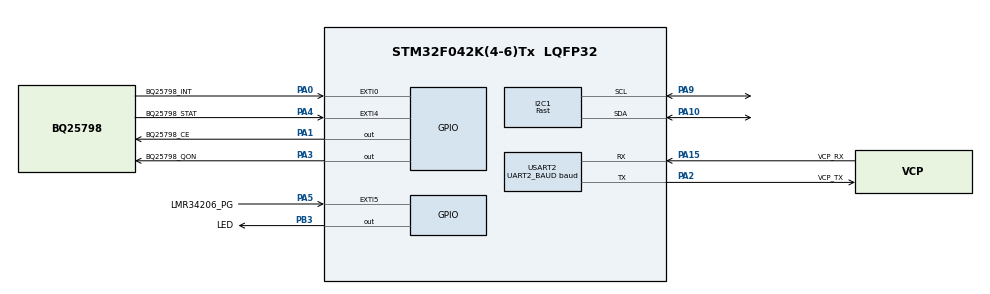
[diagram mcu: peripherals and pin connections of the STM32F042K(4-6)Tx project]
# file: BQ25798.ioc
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Dma.I2C1_RX.0.Direction=DMA_PERIPH_TO_MEMORY
Dma.I2C1_RX.0.Instance=DMA1_Channel3
Dma.I2C1_RX.0.MemDataAlignment=DMA_MDATAALIGN_BYTE
Dma.I2C1_RX.0.MemInc=DMA_MINC_ENABLE
Dma.I2C1_RX.0.Mode=DMA_NORMAL
Dma.I2C1_RX.0.PeriphDataAlignment=DMA_PDATAALIGN_BYTE
Dma.I2C1_RX.0.PeriphInc=DMA_PINC_DISABLE
Dma.I2C1_RX.0.Priority=DMA_PRIORITY_LOW
Dma.I2C1_TX.1.Direction=DMA_MEMORY_TO_PERIPH
Dma.I2C1_TX.1.Instance=DMA1_Channel2
Dma.I2C1_TX.1.MemDataAlignment=DMA_MDATAALIGN_BYTE
Dma.I2C1_TX.1.MemInc=DMA_MINC_ENABLE
Dma.I2C1_TX.1.Mode=DMA_NORMAL
Dma.I2C1_TX.1.PeriphDataAlignment=DMA_PDATAALIGN_BYTE
Dma.I2C1_TX.1.PeriphInc=DMA_PINC_DISABLE
Dma.I2C1_TX.1.Priority=DMA_PRIORITY_LOW
Dma.Request0=I2C1_RX
Dma.Request1=I2C1_TX
I2C1.I2C_Speed_Mode=I2C_Fast
I2C1.Timing=0x0000020B
Mcu.Family=STM32F0
Mcu.Name=STM32F042K(4-6)Tx
Mcu.Package=LQFP32
Mcu.UserConstants=TIMER1_PERIOD,1249;UART2_BAUD,115200;TIMER_PRESCALER,799;UART_DUMP,1
NVIC.DMA1_Channel2_3_IRQn=true\:0\:0\:false\:false\:true\:false\:true\:true
NVIC.EXTI0_1_IRQn=true\:1\:0\:true\:false\:true\:true\:true\:true
NVIC.EXTI4_15_IRQn=true\:1\:0\:true\:false\:true\:true\:true\:true
NVIC.I2C1_IRQn=true\:0\:0\:true\:false\:true\:true\:true\:true
NVIC.TIM1_BRK_UP_TRG_COM_IRQn=true\:2\:0\:true\:false\:true\:true\:true\:true
NVIC.USART2_IRQn=true\:3\:0\:true\:false\:true\:true\:true\:true
PA0.GPIO_Label=BQ25798_INT
PA0.GPIO_ModeDefaultEXTI=GPIO_MODE_IT_FALLING
PA0.Signal=GPXTI0
PA1.GPIO_Label=BQ25798_CE
PA1.PinState=GPIO_PIN_SET
PA1.Signal=GPIO_Output
PA10.GPIO_Pu=GPIO_PULLUP
PA10.Mode=I2C
PA10.Signal=I2C1_SDA
PA13.GPIO_Label=SWDIO
PA13.Mode=Serial_Wire
PA13.Signal=SYS_SWDIO
PA14.GPIO_Label=SWCLK
PA14.Mode=Serial_Wire
PA14.Signal=SYS_SWCLK
PA15.GPIO_Label=VCP_RX
PA15.Mode=Asynchronous
PA15.Signal=USART2_RX
PA2.GPIO_Label=VCP_TX
PA2.Mode=Asynchronous
PA2.Signal=USART2_TX
PA3.GPIO_Label=BQ25798_QON
PA3.PinState=GPIO_PIN_SET
PA3.Signal=GPIO_Output
PA4.GPIO_Label=BQ25798_STAT
PA4.Signal=GPXTI4
PA5.GPIO_Label=LMR34206_PG
PA5.GPIO_ModeDefaultEXTI=GPIO_MODE_IT_RISING_FALLING
PA5.Signal=GPXTI5
PA9.GPIO_Pu=GPIO_PULLUP
PA9.Mode=I2C
PA9.Signal=I2C1_SCL
PB3.GPIO_Label=LED
PB3.Signal=GPIO_Output
PF0-OSC_IN.GPIO_Label=MCO
PF0-OSC_IN.Mode=HSE-External-Clock-Source
PF0-OSC_IN.Signal=RCC_OSC_IN
ProjectManager.HeapSize=0x200
ProjectManager.StackSize=0x400
ProjectManager.TargetToolchain=STM32CubeIDE
TIM1.Period=TIMER1_PERIOD
TIM1.Prescaler=TIMER_PRESCALER
USART2.BaudRate=UART2_BAUD
USART2.VirtualMode-Asynchronous=VM_ASYNC
VP_TIM1_VS_ClockSourceINT.Mode=Internal
board=NUCLEO-F042K6

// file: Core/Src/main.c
/* USER CODE BEGIN Header */
/**
 ******************************************************************************
 * @file           : main.c
 * @brief          : Main program body
 ******************************************************************************
 * @attention
 *
 * Copyright (c) 2023 STMicroelectronics.
 * All rights reserved.
 *
 * This software is licensed under terms that can be found in the LICENSE file
 * in the root directory of this software component.
 * If no LICENSE file comes with this software, it is provided AS-IS.
 *
 ******************************************************************************
 */
/* USER CODE END Header */
#include "main.h"

/* USER CODE BEGIN Includes */
#include <stdio.h>
#include "bq25798.h"
/* USER CODE END Includes */

I2C_HandleTypeDef hi2c1;
DMA_HandleTypeDef hdma_i2c1_rx;
DMA_HandleTypeDef hdma_i2c1_tx;

TIM_HandleTypeDef htim1;

UART_HandleTypeDef huart2;

/* USER CODE BEGIN PV */
bq25798_t const *BQ25798;
/* USER CODE END PV */

void SystemClock_Config(void);
static void MX_GPIO_Init(void);
static void MX_DMA_Init(void);
static void MX_USART2_UART_Init(void);
static void MX_TIM1_Init(void);
static void MX_I2C1_Init(void);

int main(void)
{

	/* MCU Configuration--------------------------------------------------------*/

	/* Reset of all peripherals, Initializes the Flash interface and the Systick. */
	HAL_Init();

	/* Configure the system clock */
	SystemClock_Config();

	/* Initialize all configured peripherals */
	MX_GPIO_Init();
	MX_DMA_Init();
	MX_USART2_UART_Init();
	MX_TIM1_Init();
	MX_I2C1_Init();
	/* USER CODE BEGIN 2 */

	// order is important!
	BQ25798 = bq25798_ctor(&hi2c1);  // initialize device
	HAL_NVIC_EnableIRQ(TIM1_BRK_UP_TRG_COM_IRQn);  // enable timer1 interrupts

//	printf("\r\n---\r\n");	// start marker
	/* USER CODE END 2 */

	/* Infinite loop */
	while(1)
		{

		}
}

void SystemClock_Config(void)
{
	RCC_OscInitTypeDef RCC_OscInitStruct =
		{0};
	RCC_ClkInitTypeDef RCC_ClkInitStruct =
		{0};
	RCC_PeriphCLKInitTypeDef PeriphClkInit =
		{0};

	/** Initializes the RCC Oscillators according to the specified parameters
	 * in the RCC_OscInitTypeDef structure.
	 */
	RCC_OscInitStruct.OscillatorType = RCC_OSCILLATORTYPE_HSI;
	RCC_OscInitStruct.HSIState = RCC_HSI_ON;
	RCC_OscInitStruct.HSICalibrationValue = RCC_HSICALIBRATION_DEFAULT;
	RCC_OscInitStruct.PLL.PLLState = RCC_PLL_NONE;
	if(HAL_RCC_OscConfig(&RCC_OscInitStruct) != HAL_OK)
		{
			Error_Handler();
		}

	/** Initializes the CPU, AHB and APB buses clocks
	 */
	RCC_ClkInitStruct.ClockType = RCC_CLOCKTYPE_HCLK | RCC_CLOCKTYPE_SYSCLK | RCC_CLOCKTYPE_PCLK1;
	RCC_ClkInitStruct.SYSCLKSource = RCC_SYSCLKSOURCE_HSI;
	RCC_ClkInitStruct.AHBCLKDivider = RCC_SYSCLK_DIV1;
	RCC_ClkInitStruct.APB1CLKDivider = RCC_HCLK_DIV1;

	if(HAL_RCC_ClockConfig(&RCC_ClkInitStruct, FLASH_LATENCY_0) != HAL_OK)
		{
			Error_Handler();
		}
	PeriphClkInit.PeriphClockSelection = RCC_PERIPHCLK_I2C1;
	PeriphClkInit.I2c1ClockSelection = RCC_I2C1CLKSOURCE_HSI;
	if(HAL_RCCEx_PeriphCLKConfig(&PeriphClkInit) != HAL_OK)
		{
			Error_Handler();
		}
}

static void MX_I2C1_Init(void)
{

	hi2c1.Instance = I2C1;
	hi2c1.Init.Timing = 0x0000020B;
	hi2c1.Init.OwnAddress1 = 0;
	hi2c1.Init.AddressingMode = I2C_ADDRESSINGMODE_7BIT;
	hi2c1.Init.DualAddressMode = I2C_DUALADDRESS_DISABLE;
	hi2c1.Init.OwnAddress2 = 0;
	hi2c1.Init.OwnAddress2Masks = I2C_OA2_NOMASK;
	hi2c1.Init.GeneralCallMode = I2C_GENERALCALL_DISABLE;
	hi2c1.Init.NoStretchMode = I2C_NOSTRETCH_DISABLE;
	if(HAL_I2C_Init(&hi2c1) != HAL_OK)
		{
			Error_Handler();
		}

	/** Configure Analogue filter
	 */
	if(HAL_I2CEx_ConfigAnalogFilter(&hi2c1, I2C_ANALOGFILTER_ENABLE) != HAL_OK)
		{
			Error_Handler();
		}

	/** Configure Digital filter
	 */
	if(HAL_I2CEx_ConfigDigitalFilter(&hi2c1, 0) != HAL_OK)
		{
			Error_Handler();
		}

}

static void MX_TIM1_Init(void)
{

	TIM_ClockConfigTypeDef sClockSourceConfig =
		{0};
	TIM_MasterConfigTypeDef sMasterConfig =
		{0};

	htim1.Instance = TIM1;
	htim1.Init.Prescaler = TIMER_PRESCALER;
	htim1.Init.CounterMode = TIM_COUNTERMODE_UP;
	htim1.Init.Period = TIMER1_PERIOD;
	htim1.Init.ClockDivision = TIM_CLOCKDIVISION_DIV1;
	htim1.Init.RepetitionCounter = 0;
	htim1.Init.AutoReloadPreload = TIM_AUTORELOAD_PRELOAD_DISABLE;
	if(HAL_TIM_Base_Init(&htim1) != HAL_OK)
		{
			Error_Handler();
		}
	sClockSourceConfig.ClockSource = TIM_CLOCKSOURCE_INTERNAL;
	if(HAL_TIM_ConfigClockSource(&htim1, &sClockSourceConfig) != HAL_OK)
		{
			Error_Handler();
		}
	sMasterConfig.MasterOutputTrigger = TIM_TRGO_RESET;
	sMasterConfig.MasterSlaveMode = TIM_MASTERSLAVEMODE_DISABLE;
	if(HAL_TIMEx_MasterConfigSynchronization(&htim1, &sMasterConfig) != HAL_OK)
		{
			Error_Handler();
		}
	/* USER CODE BEGIN TIM1_Init 2 */
	HAL_TIM_Base_Start_IT(&htim1);	// start the timer
	/* USER CODE END TIM1_Init 2 */

}

static void MX_USART2_UART_Init(void)
{

	huart2.Instance = USART2;
	huart2.Init.BaudRate = UART2_BAUD;
	huart2.Init.WordLength = UART_WORDLENGTH_8B;
	huart2.Init.StopBits = UART_STOPBITS_1;
	huart2.Init.Parity = UART_PARITY_NONE;
	huart2.Init.Mode = UART_MODE_TX_RX;
	huart2.Init.HwFlowCtl = UART_HWCONTROL_NONE;
	huart2.Init.OverSampling = UART_OVERSAMPLING_16;
	huart2.Init.OneBitSampling = UART_ONE_BIT_SAMPLE_DISABLE;
	huart2.AdvancedInit.AdvFeatureInit = UART_ADVFEATURE_NO_INIT;
	if(HAL_UART_Init(&huart2) != HAL_OK)
		{
			Error_Handler();
		}

}

static void MX_DMA_Init(void)
{

	/* DMA controller clock enable */
	__HAL_RCC_DMA1_CLK_ENABLE();

	/* DMA interrupt init */
	/* DMA1_Channel2_3_IRQn interrupt configuration */
	HAL_NVIC_SetPriority(DMA1_Channel2_3_IRQn, 0, 0);
	HAL_NVIC_EnableIRQ(DMA1_Channel2_3_IRQn);

}

static void MX_GPIO_Init(void)
{
	GPIO_InitTypeDef GPIO_InitStruct =
		{0};

	/* GPIO Ports Clock Enable */
	__HAL_RCC_GPIOF_CLK_ENABLE();
	__HAL_RCC_GPIOA_CLK_ENABLE();
	__HAL_RCC_GPIOB_CLK_ENABLE();

	/*Configure GPIO pin Output Level */
	HAL_GPIO_WritePin(GPIOA, BQ25798_CE_Pin | BQ25798_QON_Pin, GPIO_PIN_SET);

	/*Configure GPIO pin Output Level */
	HAL_GPIO_WritePin(LED_GPIO_Port, LED_Pin, GPIO_PIN_RESET);

	/*Configure GPIO pin : PF1 */
	GPIO_InitStruct.Pin = GPIO_PIN_1;
	GPIO_InitStruct.Mode = GPIO_MODE_ANALOG;
	GPIO_InitStruct.Pull = GPIO_NOPULL;
	HAL_GPIO_Init(GPIOF, &GPIO_InitStruct);

	/*Configure GPIO pin : BQ25798_INT_Pin */
	GPIO_InitStruct.Pin = BQ25798_INT_Pin;
	GPIO_InitStruct.Mode = GPIO_MODE_IT_FALLING;
	GPIO_InitStruct.Pull = GPIO_NOPULL;
	HAL_GPIO_Init(BQ25798_INT_GPIO_Port, &GPIO_InitStruct);

	/*Configure GPIO pins : BQ25798_CE_Pin BQ25798_QON_Pin */
	GPIO_InitStruct.Pin = BQ25798_CE_Pin | BQ25798_QON_Pin;
	GPIO_InitStruct.Mode = GPIO_MODE_OUTPUT_PP;
	GPIO_InitStruct.Pull = GPIO_NOPULL;
	GPIO_InitStruct.Speed = GPIO_SPEED_FREQ_LOW;
	HAL_GPIO_Init(GPIOA, &GPIO_InitStruct);

	/*Configure GPIO pin : BQ25798_STAT_Pin */
	GPIO_InitStruct.Pin = BQ25798_STAT_Pin;
	GPIO_InitStruct.Mode = GPIO_MODE_IT_RISING;
	GPIO_InitStruct.Pull = GPIO_NOPULL;
	HAL_GPIO_Init(BQ25798_STAT_GPIO_Port, &GPIO_InitStruct);

	/*Configure GPIO pin : LMR34206_PG_Pin */
	GPIO_InitStruct.Pin = LMR34206_PG_Pin;
	GPIO_InitStruct.Mode = GPIO_MODE_IT_RISING_FALLING;
	GPIO_InitStruct.Pull = GPIO_NOPULL;
	HAL_GPIO_Init(LMR34206_PG_GPIO_Port, &GPIO_InitStruct);

	/*Configure GPIO pins : PA6 PA7 PA8 PA11
	 PA12 */
	GPIO_InitStruct.Pin = GPIO_PIN_6 | GPIO_PIN_7 | GPIO_PIN_8 | GPIO_PIN_11 | GPIO_PIN_12;
	GPIO_InitStruct.Mode = GPIO_MODE_ANALOG;
	GPIO_InitStruct.Pull = GPIO_NOPULL;
	HAL_GPIO_Init(GPIOA, &GPIO_InitStruct);

	/*Configure GPIO pins : PB0 PB1 PB4 PB5
	 PB6 PB7 PB8 */
	GPIO_InitStruct.Pin = GPIO_PIN_0 | GPIO_PIN_1 | GPIO_PIN_4 | GPIO_PIN_5 | GPIO_PIN_6 | GPIO_PIN_7 | GPIO_PIN_8;
	GPIO_InitStruct.Mode = GPIO_MODE_ANALOG;
	GPIO_InitStruct.Pull = GPIO_NOPULL;
	HAL_GPIO_Init(GPIOB, &GPIO_InitStruct);

	/*Configure GPIO pin : LED_Pin */
	GPIO_InitStruct.Pin = LED_Pin;
	GPIO_InitStruct.Mode = GPIO_MODE_OUTPUT_PP;
	GPIO_InitStruct.Pull = GPIO_NOPULL;
	GPIO_InitStruct.Speed = GPIO_SPEED_FREQ_LOW;
	HAL_GPIO_Init(LED_GPIO_Port, &GPIO_InitStruct);

	/* EXTI interrupt init*/
	HAL_NVIC_SetPriority(EXTI0_1_IRQn, 1, 0);
	HAL_NVIC_EnableIRQ(EXTI0_1_IRQn);

	HAL_NVIC_SetPriority(EXTI4_15_IRQn, 1, 0);
	HAL_NVIC_EnableIRQ(EXTI4_15_IRQn);

}

/* USER CODE BEGIN 4 */
/**
 * @brief  Retargets the C library printf function to the USART.
 * @param  None
 * @retval None
 */
#if UART_DUMP
int __io_putchar(int ch)
{
	while(HAL_UART_Transmit(&huart2, (uint8_t*) &ch, 1, 10) != HAL_OK)
		;

	return ch;
}
#endif
/* USER CODE END 4 */

void Error_Handler(void)
{
	__disable_irq();
	while(1)
		{
		}
}
